VERSION ""

NS_ :

BS_:

BU_: ECM TCM

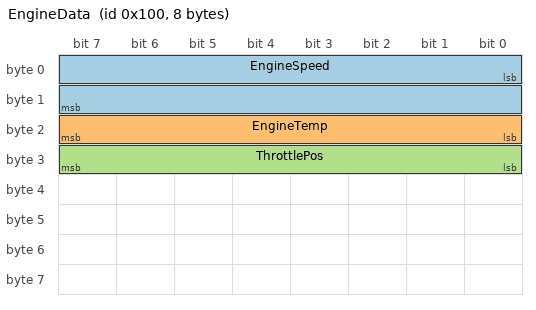
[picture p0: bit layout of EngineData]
BO_ 256 EngineData: 8 ECM
 SG_ EngineSpeed : 0|16@1+ (0.125,0) [0|8000] "rpm" TCM
 SG_ EngineTemp : 16|8@1+ (1,-40) [-40|215] "degC" TCM
 SG_ ThrottlePos : 24|8@1+ (0.4,0) [0|100] "%" TCM

BO_ 257 TransmissionData: 8 TCM
 SG_ GearRatio : 0|16@1+ (0.001,0) [0|65] "" ECM
 SG_ TransTemp : 16|8@1+ (1,-40) [-40|215] "degC" ECM

CM_ BO_ 256 "Primary engine status frame";
CM_ SG_ 256 EngineSpeed "Crankshaft rotational speed";
